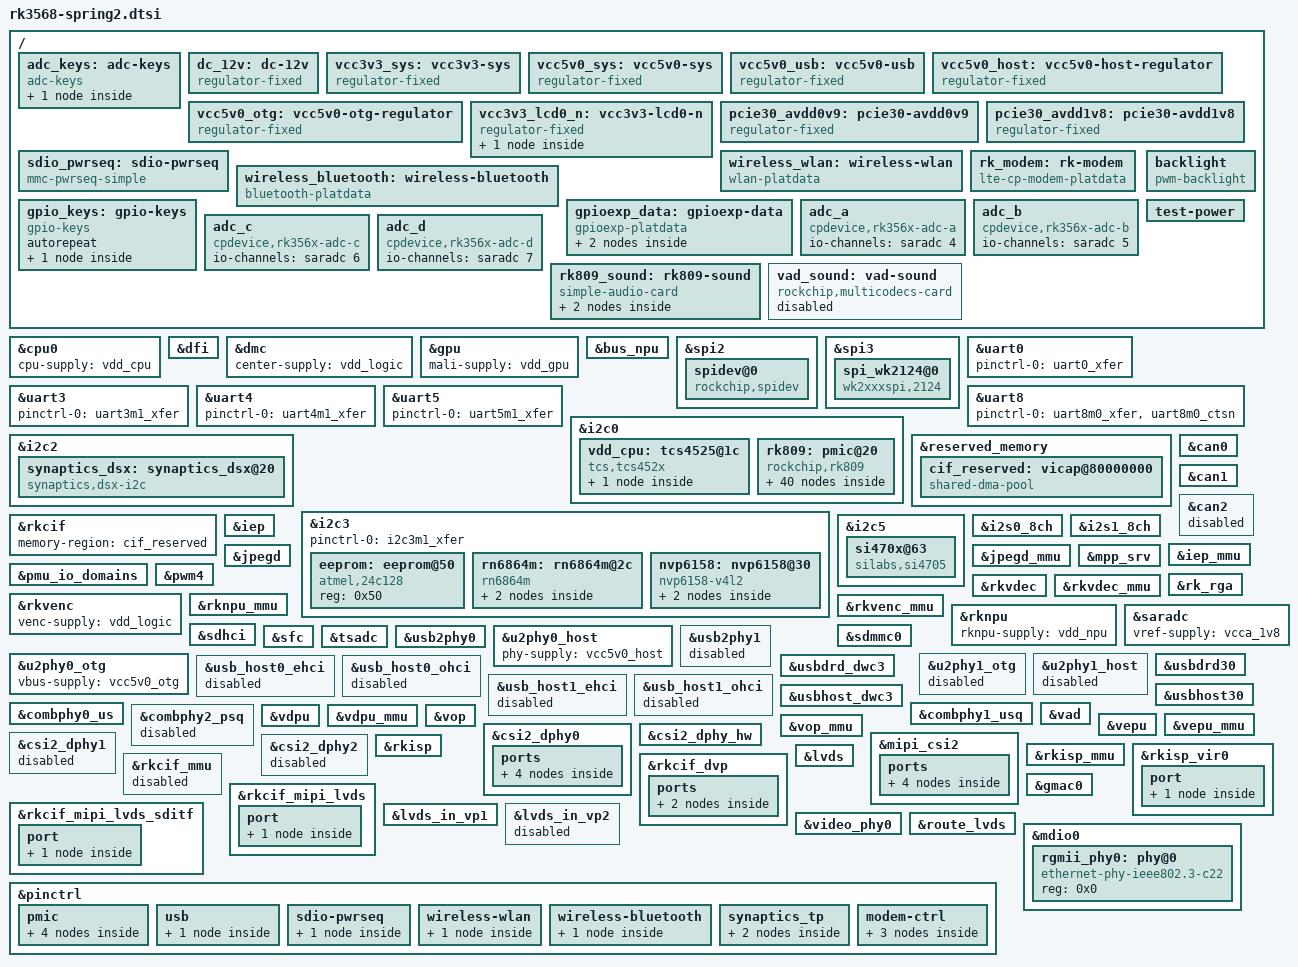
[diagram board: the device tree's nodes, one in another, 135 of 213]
// SPDX-License-Identifier: (GPL-2.0+ OR MIT)
/*
 * Copyright (c) 2020 Rockchip Electronics Co., Ltd.
 *
 */
/dts-v1/;

#include <dt-bindings/gpio/gpio.h>
#include <dt-bindings/pwm/pwm.h>
#include <dt-bindings/pinctrl/rockchip.h>
#include <dt-bindings/input/rk-input.h>
#include <dt-bindings/display/drm_mipi_dsi.h>
#include <dt-bindings/sensor-dev.h>
#include <dt-bindings/display/rockchip_vop.h>
#include <dt-bindings/display/media-bus-format.h>
#include "rk3568.dtsi"
#include "rk3568-android.dtsi"

/ {
	adc_keys: adc-keys {
		status = "okay";
		compatible = "adc-keys";
		io-channels = <&saradc 0>;
		io-channel-names = "buttons";
		keyup-threshold-microvolt = <1800000>;
		poll-interval = <100>;

		vol-up-key {
			// label = "volume up";
			// linux,code = <KEY_VOLUMEUP>;
			label = "volume down";
			linux,code = <KEY_VOLUMEDOWN>;
			press-threshold-microvolt = <1750>;
		};
	};

	dc_12v: dc-12v {
		compatible = "regulator-fixed";
		regulator-name = "dc_12v";
		regulator-always-on;
		regulator-boot-on;
		regulator-min-microvolt = <12000000>;
		regulator-max-microvolt = <12000000>;
	};

	vcc3v3_sys: vcc3v3-sys {
		compatible = "regulator-fixed";
		regulator-name = "vcc3v3_sys";
		regulator-always-on;
		regulator-boot-on;
		regulator-min-microvolt = <3300000>;
		regulator-max-microvolt = <3300000>;
		vin-supply = <&dc_12v>;
	};

	vcc5v0_sys: vcc5v0-sys {
		compatible = "regulator-fixed";
		regulator-name = "vcc5v0_sys";
		regulator-always-on;
		regulator-boot-on;
		regulator-min-microvolt = <5000000>;
		regulator-max-microvolt = <5000000>;
		vin-supply = <&dc_12v>;
	};

	vcc5v0_usb: vcc5v0-usb {
		compatible = "regulator-fixed";
		regulator-name = "vcc5v0_usb";
		regulator-always-on;
		regulator-boot-on;
		regulator-min-microvolt = <5000000>;
		regulator-max-microvolt = <5000000>;
		vin-supply = <&dc_12v>;
	};

	vcc5v0_host: vcc5v0-host-regulator {
		compatible = "regulator-fixed";
		regulator-name = "vcc5v0_host";
		regulator-boot-on;
		regulator-always-on;
		regulator-min-microvolt = <5000000>;
		regulator-max-microvolt = <5000000>;
		vin-supply = <&vcc5v0_usb>;
	};

	vcc5v0_otg: vcc5v0-otg-regulator {
		compatible = "regulator-fixed";
		regulator-name = "vcc5v0_otg";
		regulator-min-microvolt = <5000000>;
		regulator-max-microvolt = <5000000>;
		enable-active-high;
		gpio = <&gpio0 RK_PA5 GPIO_ACTIVE_HIGH>;
		vin-supply = <&vcc5v0_usb>;
		pinctrl-names = "default";
		pinctrl-0 = <&vcc5v0_otg_en>;
	};

	vcc3v3_lcd0_n: vcc3v3-lcd0-n {
		compatible = "regulator-fixed";
		regulator-name = "vcc3v3_lcd0_n";
		regulator-boot-on;
		regulator-min-microvolt = <3300000>;
		regulator-max-microvolt = <3300000>;
		enable-active-high;
		gpio = <&gpio4 RK_PD1 GPIO_ACTIVE_HIGH>;
		vin-supply = <&vcc3v3_sys>;

		regulator-state-mem {
			regulator-off-in-suspend;
		};
	};

	pcie30_avdd0v9: pcie30-avdd0v9 {
		compatible = "regulator-fixed";
		regulator-name = "pcie30_avdd0v9";
		regulator-always-on;
		regulator-boot-on;
		regulator-min-microvolt = <900000>;
		regulator-max-microvolt = <900000>;
		vin-supply = <&vcc3v3_sys>;
	};

	pcie30_avdd1v8: pcie30-avdd1v8 {
		compatible = "regulator-fixed";
		regulator-name = "pcie30_avdd1v8";
		regulator-always-on;
		regulator-boot-on;
		regulator-min-microvolt = <1800000>;
		regulator-max-microvolt = <1800000>;
		vin-supply = <&vcc3v3_sys>;
	};

	sdio_pwrseq: sdio-pwrseq {
		compatible = "mmc-pwrseq-simple";
		pinctrl-names = "default";
		pinctrl-0 = <&wifi_enable_h>;

		/*
		 * On the module itself this is one of these (depending
		 * on the actual card populated):
		 * - SDIO_RESET_L_WL_REG_ON
		 * - PDN (power down when low)
		 */
		post-power-on-delay-ms = <200>;
		reset-gpios = <&gpio3 RK_PC5 GPIO_ACTIVE_LOW>;
	};

	wireless_wlan: wireless-wlan {
		compatible = "wlan-platdata";
		rockchip,grf = <&grf>;
		//wifi_chip_type = "AW-NM372SM";
		clocks = <&rk809 1>;
		clock-names = "ext_clock";
		pinctrl-names = "default";
		pinctrl-0 = <&wifi_host_wake_irq>;
		WIFI,host_wake_irq = <&gpio3 RK_PC4 GPIO_ACTIVE_HIGH>;
		status = "okay";
	};

	wireless_bluetooth: wireless-bluetooth {
		compatible = "bluetooth-platdata";
		clocks = <&rk809 1>;
		clock-names = "ext_clock";
		//wifi-bt-power-toggle;
		uart_rts_gpios = <&gpio2 RK_PB1 GPIO_ACTIVE_LOW>;
		pinctrl-names = "default", "rts_gpio";
		pinctrl-0 = <&uart8m0_rtsn>;
		pinctrl-1 = <&uart8_gpios>;
		BT,reset_gpio    = <&gpio4 RK_PB5 GPIO_ACTIVE_HIGH>;
		BT,wake_gpio     = <&gpio3 RK_PA2 GPIO_ACTIVE_HIGH>;
		BT,wake_host_irq = <&gpio3 RK_PA1 GPIO_ACTIVE_HIGH>;
		status = "okay";
	};

	rk_modem: rk-modem {
		compatible="lte-cp-modem-platdata";
		pinctrl-names = "default";
		pinctrl-0 = <&lte_vbat &lte_power &lte_reset>;
		/*modem power*/
		LTE,vbat-gpio = <&gpio3 RK_PA3 GPIO_ACTIVE_HIGH>;
		/*power key*/
		LTE,power-gpio = <&gpio0 RK_PA4 GPIO_ACTIVE_LOW>;
		/*reset*/
		LTE,reset-gpio = <&gpio2 RK_PD1 GPIO_ACTIVE_LOW>;
		status = "okay";
	};

	gpioexp_data: gpioexp-data {
		compatible="gpioexp-platdata";
		status = "okay";

		output_io: output_io {
			output1       = <&gpio4 RK_PA7 GPIO_ACTIVE_LOW>; //GPIO4_A7_d	OUTPUT1_EN
			output2       = <&gpio0 RK_PB7 GPIO_ACTIVE_LOW>; //GPIO0_B7_d	OUTPUT2_EN
			
			//switch
			dev5v_pwren   = <&gpio3 RK_PA6 GPIO_ACTIVE_HIGH>; //GPIO3_A6_d	5V2_DEVICE_EN2
			usb_otg       = <&gpio2 RK_PD4 GPIO_ACTIVE_HIGH>;  //GPIO2_D4_d	CTR_OTG0ID
			//usb_otg_pwren = <&gpio0 RK_PA5 GPIO_ACTIVE_HIGH>; //GPIO0_A5    USB_OTG_PWREN_H			
			um482_pwren   = <&gpio4 RK_PB1 GPIO_ACTIVE_HIGH>; //GPIO4_B1_d	UM482_PWREN 3.3v
			mcam_pwren    = <&gpio3 RK_PA4 GPIO_ACTIVE_HIGH>; //GPIO3_A4_d	MCAM_PWR-EN 3.3v
			ahd_12v_en    = <&gpio3 RK_PA7 GPIO_ACTIVE_HIGH>; //GPIO3_A7_d	AHD_12V_EN  12v
			//rs485_en      = <&gpio4 RK_PA6 GPIO_ACTIVE_HIGH>; //GPIO4_A6_d	RS485_DE
			soc_heart     = <&gpio3 RK_PA5 GPIO_ACTIVE_HIGH>; //GPIO1_D6_u	MCU_IO1
			mcu_io2       = <&gpio1 RK_PA4 GPIO_ACTIVE_HIGH>; //GPIO1_A4_d	MCU_IO2
			gnss_rst      = <&gpio0 RK_PD6 GPIO_ACTIVE_HIGH>; //GPIO0_D6_d	GNSS_RST_N
			lvds_rsel     = <&gpio0 RK_PD5 GPIO_ACTIVE_LOW>; //GPIO0_D5_d	LVDS_L/R_SEL
			// spk_on        = <&gpio4 RK_PC2 GPIO_ACTIVE_LOW>; //GPIO4_C2_d	SPK_ON
			nvp6158_pwren = <&gpio3 RK_PB4 GPIO_ACTIVE_HIGH>; //GPIO3_B4_d NVP6158C_PWR-EN
			radio_pwren   = <&gpio0 RK_PD4 GPIO_ACTIVE_HIGH>; //GPIO0_D4_d RADIO_PWR-EN
			radio_cfg     = <&gpio1 RK_PB0 GPIO_ACTIVE_LOW>; //GPIO1_B0_d RADIO_CONFIG
			radio_reset   = <&gpio1 RK_PB1 GPIO_ACTIVE_HIGH>; //GPIO1_B1_d RADIO_RST_N
		};
		
		input_io {
			soc_int	      = <&gpio3 RK_PB0 GPIO_ACTIVE_LOW>;//GPIO3_B0_d	SOC_INT_OUT
			//fun_key1		= <&gpio0 RK_PC4 GPIO_ACTIVE_LOW>;//GPIO0_C4_d	FUN_KEY1
		};
	};

	gpio_keys: gpio-keys {
		status = "okay";
		compatible = "gpio-keys";
		autorepeat;

		fun_key1 {
			debounce-interval = <100>;
			gpios = <&gpio0 RK_PC4 GPIO_ACTIVE_LOW>;
			// label = "volume down";
			// linux,code = <KEY_VOLUMEDOWN>;
			label = "volume up";
			linux,code = <KEY_VOLUMEUP>;
			wakeup-source;
		};
	};

	adc_a: adc_a {
		status = "okay";
		compatible = "cpdevice,rk356x-adc-a";
		io-channels = <&saradc 4>;
	};

	adc_b: adc_b {
		status = "okay";
		compatible = "cpdevice,rk356x-adc-b";
		io-channels = <&saradc 5>;
	};

	adc_c: adc_c {
		status = "okay";
		compatible = "cpdevice,rk356x-adc-c";
		io-channels = <&saradc 6>;
	};

	adc_d: adc_d {
		status = "okay";
		compatible = "cpdevice,rk356x-adc-d";
		io-channels = <&saradc 7>;
	};

	rk809_sound: rk809-sound {
		status = "okay";
		compatible = "simple-audio-card";
		simple-audio-card,format = "i2s";
		simple-audio-card,name = "rockchip,rk809-codec";
		simple-audio-card,mclk-fs = <256>;

		simple-audio-card,cpu {
			sound-dai = <&i2s1_8ch>;
		};
		simple-audio-card,codec {
			sound-dai = <&rk809_codec>;
		};
	};

	//语音检测
	vad_sound: vad-sound {
		status = "disabled";
		compatible = "rockchip,multicodecs-card";
		rockchip,card-name = "rockchip,rk3568-vad";
		rockchip,cpu = <&i2s1_8ch>;
		rockchip,codec = <&rk809_codec>, <&vad>;
	};

	//lvds背光
	backlight: backlight {
		compatible = "pwm-backlight";
		pwms = <&pwm4 0 25000 0>;
		brightness-levels = <
			  0  20  20  21  21  22  22  23
			 23  24  24  25  25  26  26  27
			 27  28  28  29  29  30  30  31
			 31  32  32  33  33  34  34  35
			 35  36  36  37  37  38  38  39
			 40  41  42  43  44  45  46  47
			 48  49  50  51  52  53  54  55
			 56  57  58  59  60  61  62  63
			 64  65  66  67  68  69  70  71
			 72  73  74  75  76  77  78  79
			 80  81  82  83  84  85  86  87
			 88  89  90  91  92  93  94  95
			 96  97  98  99 100 101 102 103
			104 105 106 107 108 109 110 111
			112 113 114 115 116 117 118 119
			120 121 122 123 124 125 126 127
			128 129 130 131 132 133 134 135
			136 137 138 139 140 141 142 143
			144 145 146 147 148 149 150 151
			152 153 154 155 156 157 158 159
			160 161 162 163 164 165 166 167
			168 169 170 171 172 173 174 175
			176 177 178 179 180 181 182 183
			184 185 186 187 188 189 190 191
			192 193 194 195 196 197 198 199
			200 201 202 203 204 205 206 207
			208 209 210 211 212 213 214 215
			216 217 218 219 220 221 222 223
			224 225 226 227 228 229 230 231
			232 233 234 235 236 237 238 239
			240 241 242 243 244 245 246 247
			248 249 250 251 252 253 254 255
		>;
		default-brightness-level = <200>;
	};

	test-power {
		status = "okay";
	};
};

&cpu0 {
	cpu-supply = <&vdd_cpu>;
};

&dfi {
	status = "okay";
};

&dmc {
	center-supply = <&vdd_logic>;
	status = "okay";
};

&gpu {
	mali-supply = <&vdd_gpu>;
	status = "okay";
};

&bus_npu {
	bus-supply = <&vdd_logic>;
	pvtm-supply = <&vdd_cpu>;
	status = "okay";
};

//MCU通讯
&spi2 {
	status = "okay";
	max-freq = <48000000>;   //spi internal clk, don't modify
	dma-names = "tx", "rx";   //enable dma
	pinctrl-names = "default";  //pinctrl according to you board
	pinctrl-0 = <&spi2m1_cs0 &spi2m1_pins>;
	pinctrl-1 = <&spi2m1_cs0_hs &spi2m1_pins_hs>;
	rockchip,rt;
	
	spidev@0 {
		compatible = "rockchip,spidev";
		reg = <0>;   //chip select  0:cs0  1:cs1
		id = <2>;
		spi-max-frequency = <24000000>;   //spi output clock
		//spi-cpha;    //not support
		//spi-cpol; 	//if the property is here it is 1:clk is high, else 0:clk is low  when idle
	};
};

&spi3 {
	status = "okay";
	max-freq = <48000000>;
	dma-names = "tx", "rx";
	pinctrl-names = "default";
	pinctrl-0 = <&spi3m0_cs0 &spi3m0_pins>;
	pinctrl-1 = <&spi3m0_cs0_hs &spi3m0_pins_hs>;
	rockchip,rt;

	spi_wk2124@0 {
		compatible = "wk2xxxspi,2124";
		reg = <0>;
		spi-max-frequency = <10000000>;
		//spi-cpha;
		//spi-cpol;
		poll_mode = <0>;
		type = <0>;
		enable_dma = <0>;
		irq-gpio = <&gpio3 RK_PC1 IRQ_TYPE_LEVEL_LOW>;
	};
};

&uart0 {
	status = "okay";
	pinctrl-names = "default";
	pinctrl-0 = <&uart0_xfer>;
};

&uart3 {
	status = "okay";
	pinctrl-names = "default";
	pinctrl-0 = <&uart3m1_xfer>;
};

&uart4 {
	status = "okay";
	pinctrl-names = "default";
	pinctrl-0 = <&uart4m1_xfer>;
};

&uart5 {
	status = "okay";
	pinctrl-names = "default";
	pinctrl-0 = <&uart5m1_xfer>;
};

//Bluetooth
&uart8 {
	status = "okay";
	pinctrl-names = "default";
	pinctrl-0 = <&uart8m0_xfer &uart8m0_ctsn>;
};

&i2c0 {
	status = "okay";

	vdd_cpu: tcs4525@1c {
		compatible = "tcs,tcs452x";
		reg = <0x1c>;
		vin-supply = <&vcc5v0_sys>;
		regulator-compatible = "fan53555-reg";
		regulator-name = "vdd_cpu";
		regulator-min-microvolt = <712500>;
		regulator-max-microvolt = <1390000>;
		regulator-init-microvolt = <900000>;
		regulator-ramp-delay = <2300>;
		fcs,suspend-voltage-selector = <1>;
		regulator-boot-on;
		regulator-always-on;
		regulator-state-mem {
			regulator-off-in-suspend;
		};
	};

	rk809: pmic@20 {
		compatible = "rockchip,rk809";
		reg = <0x20>;
		interrupt-parent = <&gpio0>;
		interrupts = <3 IRQ_TYPE_LEVEL_LOW>;

		pinctrl-names = "default", "pmic-sleep",
				"pmic-power-off", "pmic-reset";
		pinctrl-0 = <&pmic_int>;
		pinctrl-1 = <&soc_slppin_slp>, <&rk817_slppin_slp>;
		pinctrl-2 = <&soc_slppin_gpio>, <&rk817_slppin_pwrdn>;
		pinctrl-3 = <&soc_slppin_gpio>, <&rk817_slppin_rst>;

		rockchip,system-power-controller;
		wakeup-source;
		#clock-cells = <1>;
		clock-output-names = "rk808-clkout1", "rk808-clkout2";
		//fb-inner-reg-idxs = <2>;
		/* 1: rst regs (default in codes), 0: rst the pmic */
		pmic-reset-func = <0>;
		/* not save the PMIC_POWER_EN register in uboot */
		not-save-power-en = <1>;

		vcc1-supply = <&vcc3v3_sys>;
		vcc2-supply = <&vcc3v3_sys>;
		vcc3-supply = <&vcc3v3_sys>;
		vcc4-supply = <&vcc3v3_sys>;
		vcc5-supply = <&vcc3v3_sys>;
		vcc6-supply = <&vcc3v3_sys>;
		vcc7-supply = <&vcc3v3_sys>;
		vcc8-supply = <&vcc3v3_sys>;
		vcc9-supply = <&vcc3v3_sys>;

		pwrkey {
			status = "okay";
		};

		pinctrl_rk8xx: pinctrl_rk8xx {
			gpio-controller;
			#gpio-cells = <2>;

			rk817_slppin_null: rk817_slppin_null {
				pins = "gpio_slp";
				function = "pin_fun0";
			};

			rk817_slppin_slp: rk817_slppin_slp {
				pins = "gpio_slp";
				function = "pin_fun1";
			};

			rk817_slppin_pwrdn: rk817_slppin_pwrdn {
				pins = "gpio_slp";
				function = "pin_fun2";
			};

			rk817_slppin_rst: rk817_slppin_rst {
				pins = "gpio_slp";
				function = "pin_fun3";
			};
		};

		regulators {
			vdd_logic: DCDC_REG1 {
				regulator-always-on;
				regulator-boot-on;
				regulator-min-microvolt = <500000>;
				regulator-max-microvolt = <1350000>;
				regulator-init-microvolt = <900000>;
				regulator-ramp-delay = <6001>;
				regulator-initial-mode = <0x2>;
				regulator-name = "vdd_logic";
				regulator-state-mem {
					regulator-off-in-suspend;
				};
			};

			vdd_gpu: DCDC_REG2 {
				regulator-always-on;
				regulator-boot-on;
				regulator-min-microvolt = <500000>;
				regulator-max-microvolt = <1350000>;
				regulator-init-microvolt = <900000>;
				regulator-ramp-delay = <6001>;
				regulator-initial-mode = <0x2>;
				regulator-name = "vdd_gpu";
				regulator-state-mem {
					regulator-off-in-suspend;
				};
			};

			vcc_ddr: DCDC_REG3 {
				regulator-always-on;
				regulator-boot-on;
				regulator-initial-mode = <0x2>;
				regulator-name = "vcc_ddr";
				regulator-state-mem {
					regulator-on-in-suspend;
				};
			};

			vdd_npu: DCDC_REG4 {
				regulator-always-on;
				regulator-boot-on;
				regulator-min-microvolt = <500000>;
				regulator-max-microvolt = <1350000>;
				regulator-init-microvolt = <900000>;
				regulator-ramp-delay = <6001>;
				regulator-initial-mode = <0x2>;
				regulator-name = "vdd_npu";
				regulator-state-mem {
					regulator-off-in-suspend;
				};
			};

			vdda0v9_image: LDO_REG1 {
				regulator-boot-on;
				regulator-always-on;
				regulator-min-microvolt = <900000>;
				regulator-max-microvolt = <900000>;
				regulator-name = "vdda0v9_image";
				regulator-state-mem {
					regulator-off-in-suspend;
				};
			};

			vdda_0v9: LDO_REG2 {
				regulator-always-on;
				regulator-boot-on;
				regulator-min-microvolt = <900000>;
				regulator-max-microvolt = <900000>;
				regulator-name = "vdda_0v9";
				regulator-state-mem {
					regulator-off-in-suspend;
				};
			};

			vdda0v9_pmu: LDO_REG3 {
				regulator-always-on;
				regulator-boot-on;
				regulator-min-microvolt = <900000>;
				regulator-max-microvolt = <900000>;
				regulator-name = "vdda0v9_pmu";
				regulator-state-mem {
					regulator-on-in-suspend;
					regulator-suspend-microvolt = <900000>;
				};
			};

			vccio_acodec: LDO_REG4 {
				regulator-always-on;
				regulator-boot-on;
				regulator-min-microvolt = <3300000>;
				regulator-max-microvolt = <3300000>;
				regulator-name = "vccio_acodec";
				regulator-state-mem {
					regulator-off-in-suspend;
				};
			};

			vccio_sd: LDO_REG5 {
				regulator-always-on;
				regulator-boot-on;
				regulator-min-microvolt = <3300000>;
				regulator-max-microvolt = <3300000>;
				regulator-name = "vccio_sd";
				regulator-state-mem {
					regulator-off-in-suspend;
				};
			};

			vcc3v3_pmu: LDO_REG6 {
				regulator-always-on;
				regulator-boot-on;
				regulator-min-microvolt = <3300000>;
				regulator-max-microvolt = <3300000>;
				regulator-name = "vcc3v3_pmu";
				regulator-state-mem {
					regulator-on-in-suspend;
					regulator-suspend-microvolt = <3300000>;
				};
			};

			vcca_1v8: LDO_REG7 {
				regulator-always-on;
				regulator-boot-on;
				regulator-min-microvolt = <1800000>;
				regulator-max-microvolt = <1800000>;
				regulator-name = "vcca_1v8";
				regulator-state-mem {
					regulator-off-in-suspend;
				};
			};

			vcca1v8_pmu: LDO_REG8 {
				regulator-always-on;
				regulator-boot-on;
				regulator-min-microvolt = <1800000>;
				regulator-max-microvolt = <1800000>;
				regulator-name = "vcca1v8_pmu";
				regulator-state-mem {
					regulator-on-in-suspend;
					regulator-suspend-microvolt = <1800000>;
				};
			};

			vcca1v8_image: LDO_REG9 {
				regulator-always-on;
				regulator-boot-on;
				regulator-min-microvolt = <1800000>;
				regulator-max-microvolt = <1800000>;
				regulator-name = "vcca1v8_image";
				regulator-state-mem {
					regulator-off-in-suspend;
				};
			};

			vcc_1v8: DCDC_REG5 {
				regulator-always-on;
				regulator-boot-on;
				regulator-min-microvolt = <1800000>;
				regulator-max-microvolt = <1800000>;
				regulator-name = "vcc_1v8";
				regulator-state-mem {
					regulator-off-in-suspend;
				};
			};

			vcc_3v3: SWITCH_REG1 {
				regulator-always-on;
				regulator-boot-on;
				regulator-name = "vcc_3v3";
				regulator-state-mem {
					regulator-off-in-suspend;
				};
			};

			vcc3v3_sd: SWITCH_REG2 {
				regulator-always-on;
				regulator-boot-on;
				regulator-name = "vcc3v3_sd";
				regulator-state-mem {
					regulator-off-in-suspend;
				};
			};
		};

		rk809_codec: codec {
			#sound-dai-cells = <0>;
			compatible = "rockchip,rk809-codec", "rockchip,rk817-codec";
			clocks = <&cru I2S1_MCLKOUT>;
			clock-names = "mclk";
			assigned-clocks = <&cru I2S1_MCLKOUT>, <&cru I2S1_MCLK_TX_IOE>;
			assigned-clock-rates = <12288000>;
			assigned-clock-parents = <&cru I2S1_MCLKOUT_TX>, <&cru I2S1_MCLKOUT_TX>;
			pinctrl-names = "default";
			pinctrl-0 = <&i2s1m0_mclk>;
			use-ext-amplifier;
			spk-ctl-gpios = <&gpio4 RK_PC2 GPIO_ACTIVE_HIGH>;
			// adc-for-loopback;
			// mic-in-differential;
			hp-volume = <20>;
			spk-volume = <3>;
			capture-volume = <3>;
			status = "okay";
		};
	};
};

//TP
&i2c2 {
	status = "okay";
	pinctrl-names = "default";
	pinctrl-0 = <&i2c2m0_xfer>;
	clock-frequency = <100000>;
	i2c-scl-rising-time-ns = <138>;
	i2c-scl-falling-time-ns = <4>;

	//7/10 inch lcd
	/*gt9xx: gt9xx@5d {
		compatible = "goodix,gt9xx";
		reg = <0x5d>;
		touch-gpio = <&gpio0 RK_PC2 IRQ_TYPE_LEVEL_LOW>;//INT  TP_INT
		reset-gpio = <&gpio4 RK_PB6 GPIO_ACTIVE_HIGH>;
		power-gpio = <&gpio1 RK_PD4 GPIO_ACTIVE_HIGH>;
		max-x = <1024>;
		max-y = <600>;
		tp-supply = <&vcc3v3_sys>;
		tp-size = <927>;
		tp-change-x2y=<1>;
		tp-x-reverse=<0>;
		tp-y-reverse=<0>;
		status = "okay";
	};*/

	//12 inch lcd
	/*gt9xx: gt9xx@5d {
		compatible = "goodix,gt9xx";
		reg = <0x5d>;
		touch-gpio = <&gpio0 RK_PC2 IRQ_TYPE_LEVEL_LOW>;//INT  TP_INT
		reset-gpio = <&gpio4 RK_PB6 GPIO_ACTIVE_HIGH>;
		power-gpio = <&gpio1 RK_PD4 GPIO_ACTIVE_HIGH>;
		max-x = <1024>;
		max-y = <768>;
		tp-supply = <&vcc3v3_sys>;
		tp-size = <911>;
		tp-change-x2y=<0>;
		tp-x-reverse=<0>;
		tp-y-reverse=<0>;
		status = "okay";
	};*/

	synaptics_dsx: synaptics_dsx@20 {
		compatible = "synaptics,dsx-i2c";
		reg = <0x20>;
		pinctrl-names = "default";
		pinctrl-0 = <&synaptics_int &synaptics_rest>;
		synaptics,ub-i2c-addr = <0x2c>;
		synaptics,irq-gpio = <&gpio0 RK_PC2 IRQ_TYPE_LEVEL_LOW>;
		synaptics,reset-gpio = <&gpio0 RK_PC5 GPIO_ACTIVE_HIGH>;
		synaptics,pwr-reg-name = "power";
		power-supply = <&vcc3v3_lcd0_n>;
		synaptics,irq-on-state = <0>;
		synaptics,power-delay-ms = <200>;
		synaptics,reset-delay-ms = <200>;
		synaptics,reset-on-state = <0>;
		synaptics,reset-active-ms = <20>;
		// synaptics,x-flip = <1>;
		// synaptics,y-flip = <1>;
		/* uncomment and update line below as appropriate if there are 0D buttons */
		/* synaptics,cap-button-codes = <102 158>; */
		/* uncomment and update lines below as appropriate if there are virtual buttons */
		/* synaptics,vir-button-codes = <102 100 900 100 60 158 300 900 100 60>; */
		/* synaptics,max-y-for-2d = <800>; */
	};
};

&i2c3 {
	status = "okay";
	pinctrl-names = "default";
	pinctrl-0 = <&i2c3m1_xfer>;
	//clock-frequency = <200000>;
	
	eeprom: eeprom@50 {
		compatible = "atmel,24c128";
		reg = <0x50>;	
		status = "okay";
	};

	rn6864m: rn6864m@2c {
		status = "okay";
		compatible = "rn6864m";
		reg = <0x2c>;//<0x2d>;//debug 0x2d
		
		clocks = <&cru CLK_CAM0_OUT>;
		clock-names = "xvclk";
		power-domains = <&power RK3568_PD_VI>;
		pwren-gpios = <&gpio3 RK_PA4 GPIO_ACTIVE_HIGH>;// 电源使能脚  MCAM_PWR-EN
		power-gpios = <&gpio4 RK_PC1 GPIO_ACTIVE_HIGH>;   // powerdown管脚分配及有效电平
		reset-gpios = <&gpio0 RK_PC6 GPIO_ACTIVE_HIGH>;  // 复位引脚

		rockchip,camera-module-index = <0>;
		rockchip,camera-module-facing = "back";
		rockchip,camera-module-name = "rn6864m";
		rockchip,camera-module-lens-name = "rn6864m";
		rockchip,default_rect= <1280 720>; // default resolution  1920 1080
		port {
			rn6864m_out: endpoint {
				remote-endpoint = <&mipi_in_ucam0>;
				data-lanes = <1 2 3 4>;
			};
		};
	};

	nvp6158: nvp6158@30 {
		compatible = "nvp6158-v4l2";
		status = "okay";
		reg = <0x30>;
		clocks = <&cru CLK_CIF_OUT>;
		clock-names = "xvclk";
		power-domains = <&power RK3568_PD_VI>;
		pinctrl-names = "default";
		pinctrl-0 = <&cif_clk &cif_dvp_clk &cif_dvp_bus8 &cif_dvp_bus16>;
		//pwr-gpios = <&gpio3 RK_PB4 GPIO_ACTIVE_HIGH>;
		pwr2-gpios = <&gpio4 RK_PB1 GPIO_ACTIVE_HIGH>;
		rst-gpios = <&gpio3 RK_PB3 GPIO_ACTIVE_HIGH>;
		/*rst2-gpios = <&gpio2 RK_PC5 GPIO_ACTIVE_HIGH>;*/
		/*pwdn-gpios = <&gpio4 RK_PA6 GPIO_ACTIVE_HIGH>;*/
		/*pwdn2-gpios = <&gpio4 RK_PA6 GPIO_ACTIVE_HIGH>;*/
		rockchip,camera-module-index = <0>;
		rockchip,camera-module-facing = "back";
		rockchip,camera-module-name = "default";
		rockchip,camera-module-lens-name = "default";
		rockchip,dvp_mode = "BT1120"; //BT656 or BT1120 or BT656_TEST
		rockchip,channel_nums = <4>; //channel nums, 1/2/4
		rockchip,dual_edge = <0>; // pclk dual edge, 0/1
		rockchip,default_rect= <1280 720>; // 720p
		//rockchip,dual_edge = <1>; // pclk dual edge, 0/1
		//rockchip,default_rect= <1920 1080>; // default resolution
		port {
			nvp6158_out: endpoint {
				remote-endpoint = <&dvp_in_bcam1>;
			};
		};	
	};
};

&reserved_memory {
	cif_reserved: vicap@80000000 {
		compatible = "shared-dma-pool";
		inactive;
		reusable;
		reg = <0x0 0x40000000 0x0 0x10000000>; //1G ~ 1G+256MB
		//reg = <0x0 0x60000000 0x0 0x8000000>; //1.5G ~ 1.5G+128MB
	};
};

&rkcif {
	status = "okay";
	memory-region = <&cif_reserved>;
};

&i2c5 {
	status = "okay";
	pinctrl-names = "default";
	pinctrl-0 = <&i2c5m1_xfer>;
	clock-frequency = <100000>;

	si470x@63 {
		compatible = "silabs,si4705";
		reg = <0x63>;

		// interrupt-parent = <&gpj2>;
		// interrupts = <4 IRQ_TYPE_EDGE_FALLING>;
		power-gpio = <&gpio0 RK_PD3 GPIO_ACTIVE_HIGH>;
		reset-gpio = <&gpio1 RK_PB2 GPIO_ACTIVE_HIGH>;
	};
};

&can0 {
	assigned-clocks = <&cru CLK_CAN0>;
	assigned-clock-rates = <100000000>;
	pinctrl-names = "default";
	pinctrl-0 = <&can0m0_pins>;
	status = "okay";
};

&can1 {
	assigned-clocks = <&cru CLK_CAN1>;
	assigned-clock-rates = <100000000>;
	pinctrl-names = "default";
	pinctrl-0 = <&can1m0_pins>;
	status = "okay";
};

&can2 {
	assigned-clocks = <&cru CLK_CAN2>;
	assigned-clock-rates = <100000000>;
	pinctrl-names = "default";
	pinctrl-0 = <&can2m0_pins>;
	status = "disabled";
};

&i2s0_8ch {
	status = "okay";
};

&i2s1_8ch {
	status = "okay";
	rockchip,clk-trcm = <1>;
	pinctrl-names = "default";
	pinctrl-0 = <&i2s1m0_sclktx
			 &i2s1m0_lrcktx
			 &i2s1m0_sdi0
			 &i2s1m0_sdo0>;
};

&iep {
	status = "okay";
};

&iep_mmu {
	status = "okay";
};

&jpegd {
	status = "okay";
};

&jpegd_mmu {
	status = "okay";
};

&mpp_srv {
	status = "okay";
};

 /*
  * There are 10 independent IO domains in RK3566/RK3568, including PMUIO[0:2] and VCCIO[1:7].
  * 1/ PMUIO0 and PMUIO1 are fixed-level power domains which cannot be configured;
  * 2/ PMUIO2 and VCCIO1,VCCIO[3:7] domains require that their hardware power supply voltages
  *    must be consistent with the software configuration correspondingly
  *	a/ When the hardware IO level is connected to 1.8V, the software voltage configuration
  *	   should also be configured to 1.8V accordingly;
  *	b/ When the hardware IO level is connected to 3.3V, the software voltage configuration
  *	   should also be configured to 3.3V accordingly;
  * 3/ VCCIO2 voltage control selection (0xFDC20140)
  *	BIT[0]: 0x0: from GPIO_0A7 (default)
  *	BIT[0]: 0x1: from GRF
  *    Default is determined by Pin FLASH_VOL_SEL/GPIO0_A7:
  *	L:VCCIO2 must supply 3.3V
  *	H:VCCIO2 must supply 1.8V
  */
&pmu_io_domains {
	status = "okay";
	pmuio2-supply = <&vcc3v3_pmu>;
	vccio1-supply = <&vccio_acodec>;
	vccio3-supply = <&vccio_sd>;
	vccio4-supply = <&vcc_1v8>;
	vccio5-supply = <&vcc_3v3>;
	vccio6-supply = <&vcc_3v3>;
	vccio7-supply = <&vcc_3v3>;
};

&pwm4 {
	status = "okay";
};

&rk_rga {
	status = "okay";
};

&rkvdec {
	status = "okay";
};

&rkvdec_mmu {
	status = "okay";
};

&rkvenc {
	venc-supply = <&vdd_logic>;
	status = "okay";
};

&rkvenc_mmu {
	status = "okay";
};

&rknpu {
	rknpu-supply = <&vdd_npu>;
	status = "okay";
};

&rknpu_mmu {
	status = "okay";
};

&saradc {
	status = "okay";
	vref-supply = <&vcca_1v8>;
};

//emmc
&sdhci {
	bus-width = <8>;
	supports-emmc;
	non-removable;
	max-frequency = <200000000>;
	status = "okay";
};

&sdmmc0 {
	max-frequency = <150000000>;
	supports-sdio;
	bus-width = <4>;
	disable-wp;
	cap-sd-highspeed;
	cap-sdio-irq;
	keep-power-in-suspend;
	mmc-pwrseq = <&sdio_pwrseq>;
	non-removable;
	pinctrl-names = "default";
	pinctrl-0 = <&sdmmc0_bus4 &sdmmc0_cmd &sdmmc0_clk>;
	sd-uhs-sdr104;
	status = "okay";
};

&sfc {
	status = "okay";
};

&tsadc {
	status = "okay";
};

/* USB OTG/USB Host_1 USB 2.0 Comb PHY_0 */
&usb2phy0 {
	status = "okay";
};

&u2phy0_host {
	phy-supply = <&vcc5v0_host>;
	status = "okay";
};

&u2phy0_otg {
	vbus-supply = <&vcc5v0_otg>;
	status = "okay";
};

/* USB Host_1/USB Host_2 USB 2.0 Comb PHY_0 */
&usb2phy1 {
	status = "disabled";
};

&u2phy1_otg {
	status = "disabled";
};

&u2phy1_host {
	status = "disabled";
};

/* USB 2.0 Host_2 EHCI controller for high speed */
&usb_host0_ehci {
	status = "disabled";
};

/* USB 2.0 Host_2 OHCI controller for full/low speed */
&usb_host0_ohci {
	status = "disabled";
};

/* USB 2.0 Host_3 EHCI controller for high speed */
&usb_host1_ehci {
	status = "disabled";
};

/* USB 2.0 Host_3 OHCI controller for full/low speed */
&usb_host1_ohci {
	status = "disabled";
};

/* USB 3.0 OTG controller */
&usbdrd30 {
	status = "okay";
};

&usbdrd_dwc3 {
	dr_mode = "otg";
	extcon = <&usb2phy0>;
	status = "okay";
};

/* USB 3.0 Host_1 controller */
&usbhost30 {
	status = "okay";
};

&usbhost_dwc3 {
	status = "okay";
};

/* USB 3.0 OTG/SATA Combo PHY_0 */
 &combphy0_us {
	status = "okay";
 };

/* USB 3.0 Host/SATA/QSGMII Combo PHY_1 */
&combphy1_usq {
	status = "okay";
};

/* PCIe Gen2 x 1 lane */
&combphy2_psq {
	status = "disabled";
};

&vad {
	rockchip,audio-src = <&i2s1_8ch>;
	rockchip,buffer-time-ms = <128>;
	rockchip,det-channel = <0>;
	rockchip,mode = <0>;
};

&vdpu {
	status = "okay";
};

&vdpu_mmu {
	status = "okay";
};

&vepu {
	status = "okay";
};

&vepu_mmu {
	status = "okay";
};

&vop {
	status = "okay";
	assigned-clocks = <&cru DCLK_VOP0>, <&cru DCLK_VOP1>;
	assigned-clock-parents = <&pmucru PLL_HPLL>, <&cru PLL_VPLL>;
};

&vop_mmu {
	status = "okay";
};

&csi2_dphy0 {
	//csi2_dphy0不与csi2_dphy1/csi2_dphy2同时使用，互斥
	status = "okay";

	ports {
		#address-cells = <1>;
		#size-cells = <0>;
		port@0 {
			reg = <0>;
			#address-cells = <1>;
			#size-cells = <0>;

			mipi_in_ucam0: endpoint@1 {
				reg = <1>;
				remote-endpoint = <&rn6864m_out>;
				data-lanes = <1 2 3 4>;
			};
		};
		port@1 {
			reg = <1>;
			#address-cells = <1>;
			#size-cells = <0>;

			csidphy0_out: endpoint@0 {
				reg = <0>;
				// csi2 host端的port名
				remote-endpoint = <&mipi_csi2_input>;
			};
		};
	};
};

&mipi_csi2 {
	status = "okay";
	ports {
		#address-cells = <1>;
		#size-cells = <0>;
		port@0 {
			reg = <0>;
			#address-cells = <1>;
			#size-cells = <0>;
			mipi_csi2_input: endpoint@1 {
				reg = <1>;
				// csi2 dphy 端的port名
				remote-endpoint = <&csidphy0_out>;
				// csi2 host lane数，1lane为 <1>, 4lane为 <1 2 3 4>,需与sensor端一致
				data-lanes = <1 2 3 4>;
			};
		};
		port@1 {
			reg = <1>;
			#address-cells = <1>;
			#size-cells = <0>;
			mipi_csi2_output: endpoint@0 {
				reg = <0>;
				// vicap端的port名
				remote-endpoint = <&cif_mipi_in>;
				// csi2 host lane数，1lane为 <1>, 4lane为 <1 2 3 4>,需与sensor端一致
				data-lanes = <1 2 3 4>;
			};
		};
	};
};

&csi2_dphy_hw {
	status = "okay";
};

&csi2_dphy1 {
	status = "disabled";
};

&csi2_dphy2 {
	status = "disabled";
};

&rkisp {
	status = "okay";
};

&rkisp_mmu {
	status = "okay";
};

&rkisp_vir0 {
	status = "okay";

	port {
		#address-cells = <1>;
		#size-cells = <0>;

		isp_in: endpoint@0 {
			reg = <0>;
			//vicap sditf的端点名
			remote-endpoint = <&mipi_lvds_sditf>;
		};
	};
};

&rkcif {
	status = "okay";
};

&rkcif_mmu {
	status = "disabled";
};

&rkcif_dvp {
	status = "okay";
	ports {
		#address-cells = <1>;
		#size-cells = <0>;

		port@0 {
			#address-cells = <1>;
			#size-cells = <0>;
			/* Parallel bus endpoint */
			dvp_in_bcam1: endpoint@1 {
				reg = <1>;
				remote-endpoint = <&nvp6158_out>;
				bus-width = <16>;
			};
		};
	};
};

&rkcif_mipi_lvds {
	status = "okay";
	port {
		cif_mipi_in: endpoint {
			// csi2 host端的port名
			remote-endpoint = <&mipi_csi2_output>;
			// vicap 端 lane数，2lane为 <1 2>, 4lane为 <1 2 3 4>,需与sensor端一致
			data-lanes = <1 2 3 4>;
		};
	};
};

&rkcif_mipi_lvds_sditf {
	status = "okay";
	port {
		/* MIPI CSI-2 endpoint */
		mipi_lvds_sditf: endpoint {
			//isp 虚拟设备端port名
			remote-endpoint = <&isp_in>;
			//mipi csi2 dphy的lane数，与sensor一致
			data-lanes = <1 2 3 4>;
		};
	};
};

&lvds {
	status = "okay";
};
 
&lvds_in_vp1 {
	status = "okay";
};
 
&lvds_in_vp2 {
	status = "disabled";
};
 
&video_phy0 {
	status = "okay";
};
 
&route_lvds {
	status = "okay";
	connect = <&vp1_out_lvds>;
	//逆时针旋转 180 度
	logo,rotate = <2>;
};

// lvds config,add by linx. 20201.09.10
&lvds {
	status = "okay";
};

&gmac0 {
	phy-mode = "rgmii";
	clock_in_out = "input";

	snps,reset-gpio = <&gpio2 RK_PD3 GPIO_ACTIVE_LOW>;
	snps,reset-active-low;
	/* Reset time is 20ms, 100ms for rtl8211f */
	snps,reset-delays-us = <0 20000 100000>;

	assigned-clocks = <&cru SCLK_GMAC0_RX_TX>, <&cru SCLK_GMAC0>;
	assigned-clock-parents = <&cru SCLK_GMAC0_RGMII_SPEED>, <&cru CLK_MAC0_2TOP>;
	assigned-clock-rates = <0>, <125000000>;

	pinctrl-names = "default";
	pinctrl-0 = <&gmac0_miim
			 &gmac0_tx_bus2
			 &gmac0_rx_bus2
			 &gmac0_rgmii_clk
			 &gmac0_rgmii_bus>;

	tx_delay = <0x3c>;
	rx_delay = <0x2f>;

	phy-handle = <&rgmii_phy0>;
	status = "okay";
};

&mdio0 {
	rgmii_phy0: phy@0 {
		compatible = "ethernet-phy-ieee802.3-c22";
		reg = <0x0>;
	};
};

&pinctrl {
	pmic {
		pmic_int: pmic_int {
			rockchip,pins =
				<0 RK_PA3 RK_FUNC_GPIO &pcfg_pull_up>;
		};

		soc_slppin_gpio: soc_slppin_gpio {
			rockchip,pins =
				<0 RK_PA2 RK_FUNC_GPIO &pcfg_output_low_pull_down>;
		};

		soc_slppin_slp: soc_slppin_slp {
			rockchip,pins =
				<0 RK_PA2 1 &pcfg_pull_up>;
		};

		soc_slppin_rst: soc_slppin_rst {
			rockchip,pins =
				<0 RK_PA2 2 &pcfg_pull_none>;
		};
	};

	usb {
		vcc5v0_otg_en: vcc5v0-otg-en {
			rockchip,pins = <0 RK_PA5 RK_FUNC_GPIO &pcfg_pull_none>;
		};
	};

	sdio-pwrseq {
		wifi_enable_h: wifi-enable-h {
			rockchip,pins = <3 RK_PC5 RK_FUNC_GPIO &pcfg_pull_none>;
		};
	};

	wireless-wlan {
		wifi_host_wake_irq: wifi-host-wake-irq {
			rockchip,pins = <3 RK_PC4 RK_FUNC_GPIO &pcfg_pull_down>;
		};
	};

	wireless-bluetooth {
		uart8_gpios: uart8-gpios {
			rockchip,pins = <2 RK_PB1 RK_FUNC_GPIO &pcfg_pull_none>;
		};
	};

	synaptics_tp {
		synaptics_int: synaptics-int {
			rockchip,pins = <0 RK_PC2 RK_FUNC_GPIO &pcfg_pull_up>;
		};
		synaptics_rest: synaptics_rest {
			rockchip,pins = <0 RK_PC5 RK_FUNC_GPIO &pcfg_pull_none>;
		};
	};

	modem-ctrl {
		lte_vbat: lte-vbat {
			rockchip,pins = <3 RK_PA3 RK_FUNC_GPIO &pcfg_pull_none>;
		};

		lte_power: lte-power-en {
			rockchip,pins = <0 RK_PA4 RK_FUNC_GPIO &pcfg_pull_none>;
		};

		lte_reset: lte-reset {
			rockchip,pins = <2 RK_PD1 RK_FUNC_GPIO &pcfg_pull_none>;
		};
	};
};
